# RTC_C_356.0 register map
Vendor: Texas Instruments
Peripheral module from a debugger description file (folder MSP432).
Registers are 16-bit, read-write, no defined reset value unless marked. A register's access mark holds for its fields unless they carry their own. Offsets are as the file gives them; lines under a group give offsets from that group; [hi:lo] are bit positions; {n}, {i} and the like mark numbered series; 'fields as' and 'values as' point back to an identical list; <NAME> marks a mode.

## RTC_C
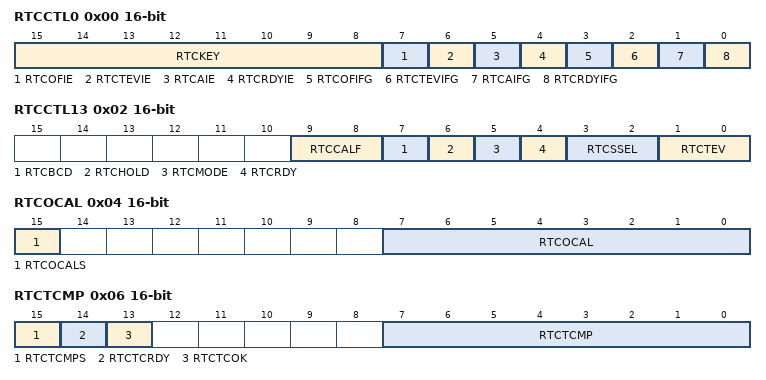
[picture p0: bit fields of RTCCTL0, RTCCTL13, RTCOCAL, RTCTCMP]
0x00 RTCCTL0
  [15:8] RTCKEY — Real-time clock key
  [7] RTCOFIE — 32-kHz crystal oscillator fault interrupt enable
    0=Interrupt not enabled; 1=Interrupt enabled (LPM3/LPM3.5 wake-up enabled)
  [6] RTCTEVIE — Real-time clock time event interrupt enable
    values as RTCOFIE
  [5] RTCAIE — Real-time clock alarm interrupt enable
    values as RTCOFIE
  [4] RTCRDYIE — Real-time clock ready interrupt enable
    0=Interrupt not enabled; 1=Interrupt enabled
  [3] RTCOFIFG — 32-kHz crystal oscillator fault interrupt flag
    0=No interrupt pending; 1=Interrupt pending. A 32-kHz crystal oscillator fault occurred after last reset.
  [2] RTCTEVIFG — Real-time clock time event interrupt flag
    0=No time event occurred; 1=Time event occurred
  [1] RTCAIFG — Real-time clock alarm interrupt flag
    0=No time event occurred; 1=Time event occurred
  [0] RTCRDYIFG — Real-time clock ready interrupt flag
    0=RTC cannot be read safely; 1=RTC can be read safely
0x02 RTCCTL13 access per field
  [9:8] RTCCALF rw — Real-time clock calibration frequency
    0=NONE (No frequency output to RTCCLK pin); 1=512 Hz; 2=256 Hz; 3=1 Hz
  [7] RTCBCD rw — Real-time clock BCD select
    0=HEX (Binary (hexadecimal) code selected); 1=BCD (Binary coded decimal (BCD) code selected)
  [6] RTCHOLD rw — Real-time clock hold
    0=Real-time clock is operational; 1=When set, the calendar is stopped as well as the prescale counters, RT0PS and RT1PS are don't care
  [5] RTCMODE ro
    1=Calendar mode. Always reads a value of 1.
  [4] RTCRDY ro — Real-time clock ready
    0=RTC time values in transition; 1=RTC time values safe for reading. This bit indicates when the real-time clock time values are safe for reading.
  [3:2] RTCSSEL rw — Real-time clock source select
    0=BCLK
  [1:0] RTCTEV rw — Real-time clock time event
    0=Minute changed; 1=Hour changed; 2=Every day at midnight (00:00); 3=Every day at noon (12:00)
0x04 RTCOCAL
  [15] RTCOCALS — Real-time clock offset error calibration sign
    0=DOWN (Down calibration. Frequency adjusted down.); 1=UP (Up calibration. Frequency adjusted up.)
  [7:0] RTCOCAL — Real-time clock offset error calibration
0x06 RTCTCMP access per field
  [15] RTCTCMPS rw — Real-time clock temperature compensation sign
    0=DOWN (Down calibration. Frequency adjusted down); 1=UP (Up calibration. Frequency adjusted up)
  [14] RTCTCRDY ro — Real-time clock temperature compensation ready
  [13] RTCTCOK ro — Real-time clock temperature compensation write OK
    0=Write to RTCTCMPx is unsuccessful; 1=Write to RTCTCMPx is successful
  [7:0] RTCTCMP rw — Real-time clock temperature compensation
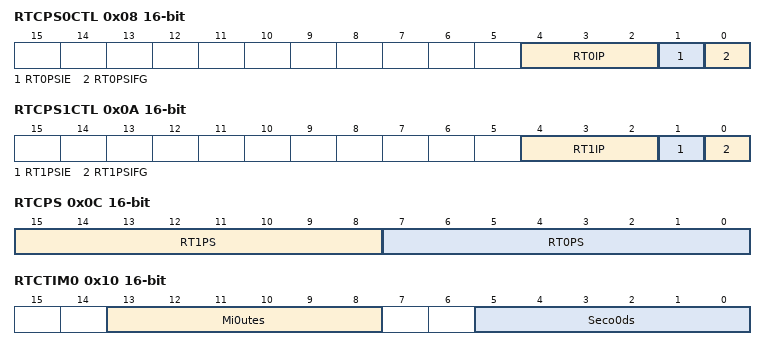
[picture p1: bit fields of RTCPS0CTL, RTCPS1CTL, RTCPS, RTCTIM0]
0x08 RTCPS0CTL — Real-Time Clock Prescale Timer 0 Control Register
  [4:2] RT0IP — Prescale timer 0 interrupt interval
    0=Divide by 2; 1=Divide by 4; 2=Divide by 8; 3=Divide by 16; 4=Divide by 32; 5=Divide by 64; 6=Divide by 128; 7=Divide by 256
  [1] RT0PSIE — Prescale timer 0 interrupt enable
    values as RTCCTL0.RTCOFIE
  [0] RT0PSIFG — Prescale timer 0 interrupt flag
    0=No time event occurred; 1=Time event occurred
0x0A RTCPS1CTL — Real-Time Clock Prescale Timer 1 Control Register
  [4:2] RT1IP — Prescale timer 1 interrupt interval
    values as RTCPS0CTL.RT0IP
  [1] RT1PSIE — Prescale timer 1 interrupt enable
    values as RTCCTL0.RTCOFIE
  [0] RT1PSIFG — Prescale timer 1 interrupt flag
    0=No time event occurred; 1=Time event occurred
0x0C RTCPS — Real-Time Clock Prescale Timer Counter Register
  [15:8] RT1PS — Prescale timer 1 counter value
  [7:0] RT0PS — Prescale timer 0 counter value
0x0E RTCIV ro — Real-Time Clock Interrupt Vector Register
  [15:0] RTCIV — Real-time clock interrupt vector value
    0=NONE (No interrupt pending); 2=RTCOFIFG (Interrupt Source: RTC oscillator failure; Interrupt Flag: RTCOFIFG; Interrupt Priority: Highest); 4=RTCRDYIFG (Interrupt Source: RTC ready; Interrupt Flag: RTCRDYIFG); 6=RTCTEVIFG (Interrupt Source: RTC interval timer; Interrupt Flag: RTCTEVIFG); 8=RTCAIFG (Interrupt Source: RTC user alarm; Interrupt Flag: RTCAIFG); 10=RT0PSIFG (Interrupt Source: RTC prescaler 0; Interrupt Flag: RT0PSIFG); 12=RT1PSIFG (Interrupt Source: RTC prescaler 1; Interrupt Flag: RT1PSIFG)
0x10 RTCTIM0 — RTCTIM0 Register Hexadecimal Format
  [13:8] Mi0utes — Minutes (0 to 59)
  [5:0] Seco0ds — Seconds (0 to 59)
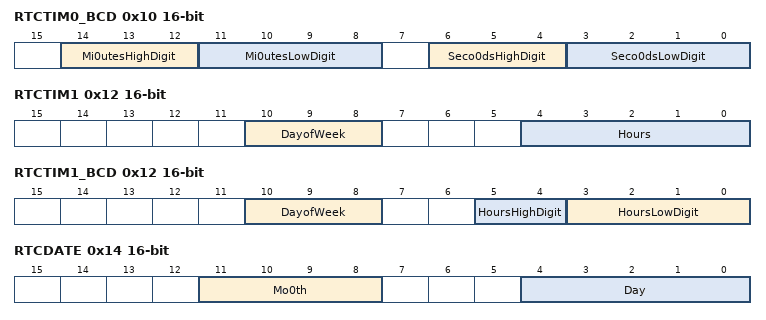
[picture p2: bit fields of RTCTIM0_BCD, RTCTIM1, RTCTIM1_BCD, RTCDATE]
0x10 RTCTIM0_BCD — Real-Time Clock Seconds, Minutes Register - BCD Format
  [14:12] Mi0utesHighDigit — Minutes high digit (0 to 5)
  [11:8] Mi0utesLowDigit — Minutes low digit (0 to 9)
  [6:4] Seco0dsHighDigit — Seconds high digit (0 to 5)
  [3:0] Seco0dsLowDigit — Seconds low digit (0 to 9)
0x12 RTCTIM1 — Real-Time Clock Hour, Day of Week
  [10:8] DayofWeek — Day of week (0 to 6)
  [4:0] Hours — Hours (0 to 23)
0x12 RTCTIM1_BCD — Real-Time Clock Hour, Day of Week - BCD Format
  [10:8] DayofWeek — Day of week (0 to 6)
  [5:4] HoursHighDigit — Hours high digit (0 to 2)
  [3:0] HoursLowDigit — Hours low digit (0 to 9)
0x14 RTCDATE — RTCDATE - Hexadecimal Format
  [11:8] Mo0th — Month (1 to 12)
  [4:0] Day — Day of month (1 to 28, 29, 30, 31)
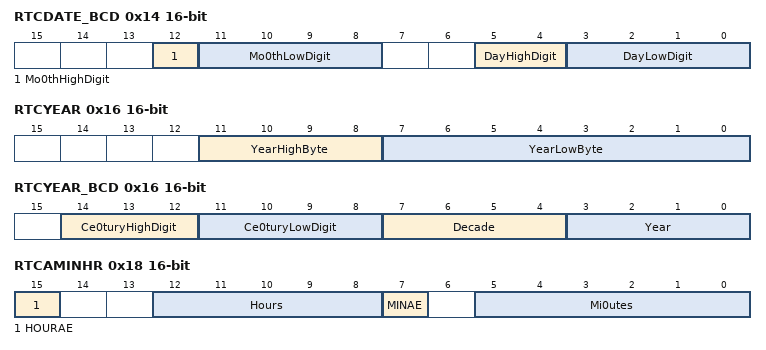
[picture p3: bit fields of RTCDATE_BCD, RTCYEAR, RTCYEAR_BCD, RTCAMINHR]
0x14 RTCDATE_BCD — Real-Time Clock Date - BCD Format
  [12] Mo0thHighDigit — Month high digit (0 or 1)
  [11:8] Mo0thLowDigit — Month low digit (0 to 9)
  [5:4] DayHighDigit — Day of month high digit (0 to 3)
  [3:0] DayLowDigit — Day of month low digit (0 to 9)
0x16 RTCYEAR — RTCYEAR Register Hexadecimal Format
  [11:8] YearHighByte — Year high byte. Valid values for Year are 0 to 4095.
  [7:0] YearLowByte — Year low byte. Valid values for Year are 0 to 4095.
0x16 RTCYEAR_BCD — Real-Time Clock Year Register - BCD Format
  [14:12] Ce0turyHighDigit — Century high digit (0 to 4)
  [11:8] Ce0turyLowDigit — Century low digit (0 to 9)
  [7:4] Decade — Decade (0 to 9)
  [3:0] Year — Year lowest digit (0 to 9)
0x18 RTCAMINHR — RTCMINHR - Hexadecimal Format
  [15] HOURAE — Alarm enable
  [12:8] Hours — Hours (0 to 23)
  [7] MINAE — Alarm enable
  [5:0] Mi0utes — Minutes (0 to 59)
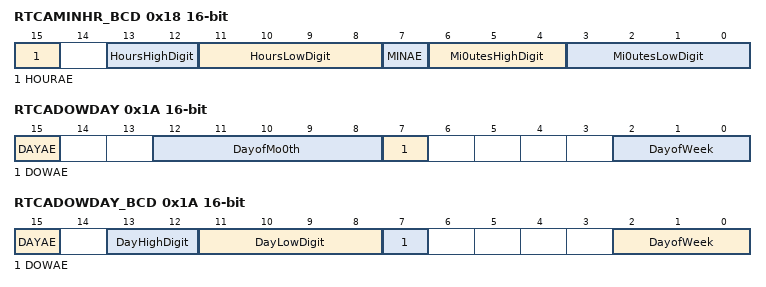
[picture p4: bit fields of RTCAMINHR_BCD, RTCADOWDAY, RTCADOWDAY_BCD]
0x18 RTCAMINHR_BCD — Real-Time Clock Minutes, Hour Alarm - BCD Format
  [15] HOURAE — Alarm enable
  [13:12] HoursHighDigit — Hours high digit (0 to 2)
  [11:8] HoursLowDigit — Hours low digit (0 to 9)
  [7] MINAE — Alarm enable
  [6:4] Mi0utesHighDigit — Minutes high digit (0 to 5)
  [3:0] Mi0utesLowDigit — Minutes low digit (0 to 9)
0x1A RTCADOWDAY — RTCADOWDAY - Hexadecimal Format
  [15] DAYAE — Alarm enable
  [12:8] DayofMo0th — Day of month (1 to 28, 29, 30, 31)
  [7] DOWAE — Alarm enable
  [2:0] DayofWeek — Day of week (0 to 6)
0x1A RTCADOWDAY_BCD — Real-Time Clock Day of Week, Day of Month Alarm - BCD Format
  [15] DAYAE — Alarm enable
  [13:12] DayHighDigit — Day of month high digit (0 to 3)
  [11:8] DayLowDigit — Day of month low digit (0 to 9)
  [7] DOWAE — Alarm enable
  [2:0] DayofWeek — Day of week (0 to 6)
0x1C RTCBIN2BCD access not given — Binary-to-BCD Conversion Register
0x1E RTCBCD2BIN access not given — BCD-to-Binary Conversion Register
